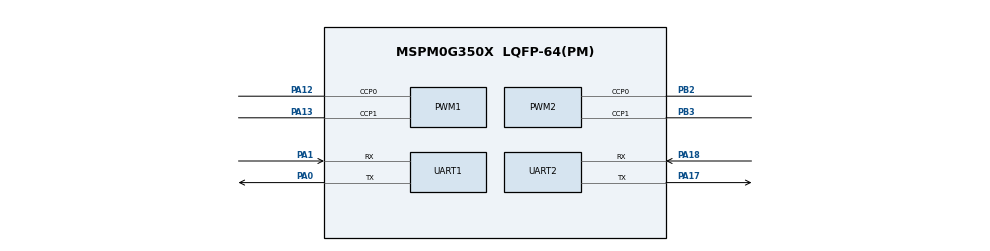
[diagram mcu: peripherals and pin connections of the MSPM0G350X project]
/**
 * @cliArgs --device "MSPM0G350X" --part "Default" --package "LQFP-64(PM)" --product "mspm0_sdk@2.11.00.07"
 * @versions {"tool":"1.26.2+4477"}
 */

/**
 * Import the modules used in this configuration.
 */
const GPIO          = scripting.addModule("/ti/driverlib/GPIO", {}, false);
const GPIO1         = GPIO.addInstance();
const GPIO2         = GPIO.addInstance();
const PWM           = scripting.addModule("/ti/driverlib/PWM", {}, false);
const PWM1          = PWM.addInstance();
const PWM2          = PWM.addInstance();
const SYSCTL        = scripting.addModule("/ti/driverlib/SYSCTL");
const UART          = scripting.addModule("/ti/driverlib/UART", {}, false);
const UART1         = UART.addInstance();
const UART2         = UART.addInstance();
const ProjectConfig = scripting.addModule("/ti/project_config/ProjectConfig");

/**
 * Write custom configuration values to the imported modules.
 */
const divider7       = system.clockTree["PLL_PDIV"];
divider7.divideValue = 2;

const divider9       = system.clockTree["UDIV"];
divider9.divideValue = 2;

const multiplier2         = system.clockTree["PLL_QDIV"];
multiplier2.multiplyValue = 10;

const mux8       = system.clockTree["HSCLKMUX"];
mux8.inputSelect = "HSCLKMUX_SYSPLL0";

GPIO1.$name                   = "STEPPER_YAW_GPIO";
GPIO1.associatedPins.create(4);
GPIO1.associatedPins[0].$name = "YAW_DIR";
GPIO1.associatedPins[1].$name = "YAW_DCY";
GPIO1.associatedPins[2].$name = "YAW_SLP";
GPIO1.associatedPins[3].$name = "YAW_RST";

const Board = scripting.addModule("/ti/driverlib/Board", {}, false);

GPIO2.$name                   = "STEPPER_PITCH_GPIO";
GPIO2.associatedPins.create(4);
GPIO2.associatedPins[0].$name = "PITCH_DIR";
GPIO2.associatedPins[1].$name = "PITCH_DCY";
GPIO2.associatedPins[2].$name = "PITCH_SLP";
GPIO2.associatedPins[3].$name = "PITCH_RST";

PWM1.$name                              = "STEPPER_YAW_PWM";
PWM1.clockDivider                       = 8;
PWM1.clockPrescale                      = 2;
PWM1.timerCount                         = 10000;
PWM1.interrupts                         = ["LOAD_EVENT"];
PWM1.peripheral.$assign                 = "TIMG0";
PWM1.peripheral.ccp0Pin.$assign         = "PA12";
PWM1.peripheral.ccp1Pin.$assign         = "PA13";
PWM1.PWM_CHANNEL_0.$name                = "ti_driverlib_pwm_PWMTimerCC0";
PWM1.PWM_CHANNEL_0.ccValue              = 5000;
PWM1.PWM_CHANNEL_1.$name                = "ti_driverlib_pwm_PWMTimerCC1";
PWM1.ccp0PinConfig.direction            = scripting.forceWrite("OUTPUT");
PWM1.ccp0PinConfig.hideOutputInversion  = scripting.forceWrite(false);
PWM1.ccp0PinConfig.onlyInternalResistor = scripting.forceWrite(false);
PWM1.ccp0PinConfig.passedPeripheralType = scripting.forceWrite("Digital");
PWM1.ccp0PinConfig.$name                = "ti_driverlib_gpio_GPIOPinGeneric4";
PWM1.ccp1PinConfig.direction            = scripting.forceWrite("OUTPUT");
PWM1.ccp1PinConfig.hideOutputInversion  = scripting.forceWrite(false);
PWM1.ccp1PinConfig.onlyInternalResistor = scripting.forceWrite(false);
PWM1.ccp1PinConfig.passedPeripheralType = scripting.forceWrite("Digital");
PWM1.ccp1PinConfig.$name                = "ti_driverlib_gpio_GPIOPinGeneric5";

PWM2.$name                              = "STEPPER_PITCH_PWM";
PWM2.clockDivider                       = 8;
PWM2.clockPrescale                      = 2;
PWM2.timerCount                         = 10000;
PWM2.interrupts                         = ["LOAD_EVENT"];
PWM2.peripheral.$assign                 = "TIMG6";
PWM2.peripheral.ccp0Pin.$assign         = "PB2";
PWM2.peripheral.ccp1Pin.$assign         = "PB3";
PWM2.PWM_CHANNEL_0.$name                = "ti_driverlib_pwm_PWMTimerCC2";
PWM2.PWM_CHANNEL_0.ccValue              = 5000;
PWM2.PWM_CHANNEL_1.$name                = "ti_driverlib_pwm_PWMTimerCC3";
PWM2.ccp0PinConfig.direction            = scripting.forceWrite("OUTPUT");
PWM2.ccp0PinConfig.hideOutputInversion  = scripting.forceWrite(false);
PWM2.ccp0PinConfig.onlyInternalResistor = scripting.forceWrite(false);
PWM2.ccp0PinConfig.passedPeripheralType = scripting.forceWrite("Digital");
PWM2.ccp0PinConfig.$name                = "ti_driverlib_gpio_GPIOPinGeneric6";
PWM2.ccp1PinConfig.direction            = scripting.forceWrite("OUTPUT");
PWM2.ccp1PinConfig.hideOutputInversion  = scripting.forceWrite(false);
PWM2.ccp1PinConfig.onlyInternalResistor = scripting.forceWrite(false);
PWM2.ccp1PinConfig.passedPeripheralType = scripting.forceWrite("Digital");
PWM2.ccp1PinConfig.$name                = "ti_driverlib_gpio_GPIOPinGeneric7";

SYSCTL.clockTreeEn = true;

UART1.$name                            = "UART_VISION";
UART1.targetBaudRate                   = 115200;
UART1.peripheral.$assign               = "UART0";
UART1.peripheral.rxPin.$assign         = "PA1";
UART1.peripheral.txPin.$assign         = "PA0";
UART1.txPinConfig.direction            = scripting.forceWrite("OUTPUT");
UART1.txPinConfig.hideOutputInversion  = scripting.forceWrite(false);
UART1.txPinConfig.onlyInternalResistor = scripting.forceWrite(false);
UART1.txPinConfig.passedPeripheralType = scripting.forceWrite("Digital");
UART1.txPinConfig.$name                = "ti_driverlib_gpio_GPIOPinGeneric0";
UART1.rxPinConfig.hideOutputInversion  = scripting.forceWrite(false);
UART1.rxPinConfig.onlyInternalResistor = scripting.forceWrite(false);
UART1.rxPinConfig.passedPeripheralType = scripting.forceWrite("Digital");
UART1.rxPinConfig.$name                = "ti_driverlib_gpio_GPIOPinGeneric1";

UART2.$name                            = "UART_PC";
UART2.targetBaudRate                   = 115200;
UART2.peripheral.$assign               = "UART1";
UART2.peripheral.rxPin.$assign         = "PA18";
UART2.peripheral.txPin.$assign         = "PA17";
UART2.txPinConfig.direction            = scripting.forceWrite("OUTPUT");
UART2.txPinConfig.hideOutputInversion  = scripting.forceWrite(false);
UART2.txPinConfig.onlyInternalResistor = scripting.forceWrite(false);
UART2.txPinConfig.passedPeripheralType = scripting.forceWrite("Digital");
UART2.txPinConfig.$name                = "ti_driverlib_gpio_GPIOPinGeneric2";
UART2.rxPinConfig.hideOutputInversion  = scripting.forceWrite(false);
UART2.rxPinConfig.onlyInternalResistor = scripting.forceWrite(false);
UART2.rxPinConfig.passedPeripheralType = scripting.forceWrite("Digital");
UART2.rxPinConfig.$name                = "ti_driverlib_gpio_GPIOPinGeneric3";

ProjectConfig.genDisable = true;

/**
 * Pinmux solution for unlocked pins/peripherals. This ensures that minor changes to the automatic solver in a future
 * version of the tool will not impact the pinmux you originally saw.  These lines can be completely deleted in order to
 * re-solve from scratch.
 */
GPIO1.associatedPins[0].pin.$suggestSolution = "PB13";
GPIO1.associatedPins[1].pin.$suggestSolution = "PB15";
GPIO1.associatedPins[2].pin.$suggestSolution = "PB16";
GPIO1.associatedPins[3].pin.$suggestSolution = "PA14";
Board.peripheral.$suggestSolution            = "DEBUGSS";
Board.peripheral.swclkPin.$suggestSolution   = "PA20";
Board.peripheral.swdioPin.$suggestSolution   = "PA19";
GPIO2.associatedPins[0].pin.$suggestSolution = "PB14";
GPIO2.associatedPins[1].pin.$suggestSolution = "PA15";
GPIO2.associatedPins[2].pin.$suggestSolution = "PA16";
GPIO2.associatedPins[3].pin.$suggestSolution = "PB17";
